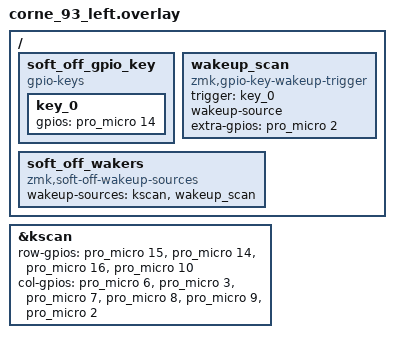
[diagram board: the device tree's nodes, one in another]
#include "corne_93.dtsi"

&kscan {
    row-gpios
        = <&pro_micro 15 (GPIO_ACTIVE_HIGH | GPIO_PULL_DOWN)>
        , <&pro_micro 14 (GPIO_ACTIVE_HIGH | GPIO_PULL_DOWN)>
        , <&pro_micro 16 (GPIO_ACTIVE_HIGH | GPIO_PULL_DOWN)>
        , <&pro_micro 10 (GPIO_ACTIVE_HIGH | GPIO_PULL_DOWN)>
        ;

    col-gpios
        = <&pro_micro 6 GPIO_ACTIVE_HIGH>
        , <&pro_micro 3 GPIO_ACTIVE_HIGH>
        , <&pro_micro 7 GPIO_ACTIVE_HIGH>
        , <&pro_micro 8 GPIO_ACTIVE_HIGH>
        , <&pro_micro 9 GPIO_ACTIVE_HIGH>
        , <&pro_micro 2 GPIO_ACTIVE_HIGH>
        ;
};
/ {
    soft_off_gpio_key: soft_off_gpio_key {
        compatible = "gpio-keys";
				key_0: key_0 {
					gpios = <&pro_micro 14 (GPIO_ACTIVE_HIGH | GPIO_PULL_DOWN)>;
				};
    };

    wakeup_scan: wakeup_scan {
        compatible = "zmk,gpio-key-wakeup-trigger";
		  	trigger = <&key_0>;
        wakeup-source;
        extra-gpios = <&pro_micro 2 GPIO_ACTIVE_HIGH>;
    };

    soft_off_wakers {
        compatible = "zmk,soft-off-wakeup-sources";
        wakeup-sources = <&kscan>, <&wakeup_scan>;
    };
};
